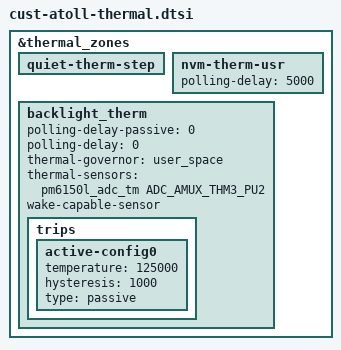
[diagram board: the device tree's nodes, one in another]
&thermal_zones {
	/* Use the skin cooling maps inherited from the Atoll base tree. */
	quiet-therm-step {
		status = "okay";
	};

	nvm-therm-usr {
		polling-delay = <5000>;
	};

	backlight_therm {
		polling-delay-passive = <0>;
		polling-delay = <0>;
		thermal-governor = "user_space";
		thermal-sensors = <&pm6150l_adc_tm ADC_AMUX_THM3_PU2>;
		wake-capable-sensor;
		trips {
			active-config0 {
				temperature = <125000>;
				hysteresis = <1000>;
				type = "passive";
			};
		};
	};
};
